# MSP430FR2355 register map
Vendor: msp430gen; File version: v0.4.0-28-gb0087ce-dirty
Registers are 16-bit, read-write, reset 0x0 unless marked. A register's access mark holds for its fields unless they carry their own. Offsets are from the block's base; [hi:lo] are bit positions; {n}, {i} and the like mark numbered series; 'fields as' and 'values as' point back to an identical list.

## SYS
Base 0x00000140
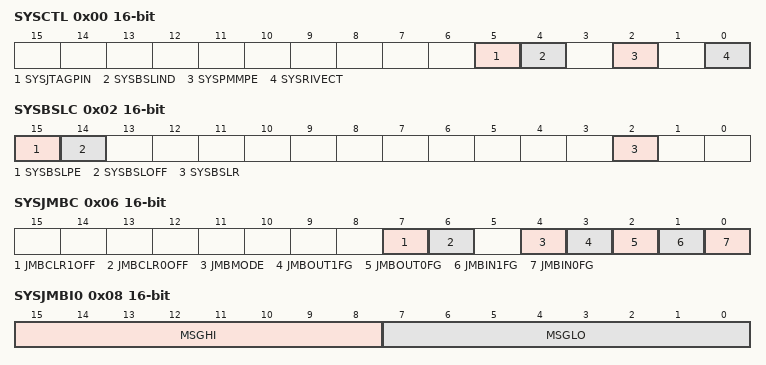
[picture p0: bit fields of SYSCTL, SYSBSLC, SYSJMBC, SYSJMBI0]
0x00 SYSCTL — System Control
  [5] SYSJTAGPIN — Dedicated JTAG pins enable
    0=SHARED (Shared JTAG pins (JTAG mode selectable by JTAG/SBW sequence)); 1=DEDICATED (Dedicated JTAG pins (explicit 4-wire JTAG mode selection))
  [4] SYSBSLIND — BSL entry indication
    0=CLR (No BSL entry sequence detected); 1=SET (BSL entry sequence detected)
  [2] SYSPMMPE — PMM access protect
    0=DIS (Access from anywhere in memory); 1=EN (Access only from the protected BSL segments)
  [0] SYSRIVECT — RAM-based interrupt vectors
    0=FRAM (Interrupt vectors generated with end address TOP of lower 64KB of FRAM FFFFh); 1=RAM (Interrupt vectors generated with end address TOP of RAM)
0x02 SYSBSLC — Bootstrap Loader Configuration Register
  [15] SYSBSLPE — Bootstrap loader memory protection enable for the size covered in SYSBSLSIZE. By default, this bit is cleared by hardware with a BOR event (as indicated above); however, the boot code that checks for an available BSL may set this bit in software to protect the BSL. Because devices normally come with a TI BSL preprogrammed and protected, the boot code sets this bit.
    0=NOTPROT (Area not protected. Read, program, and erase of BSL memory is possible.); 1=PROT (Area protected)
  [14] SYSBSLOFF — Bootstrap loader memory disable for the size covered in SYSBSLSIZE
    0=ON (BSL memory is addressed when this area is read.); 1=OFF (BSL memory behaves like vacant memory. Reads cause 3FFFh to be read. Fetches cause JMP $ to be executed.)
  [2] SYSBSLR — RAM assigned to BSL
    0=NORAM (No RAM assigned to BSL area); 1=RAM (Lowest 16 bytes of RAM assigned to BSL)
0x06 SYSJMBC — JTAG Mailbox Control
  [7] JMBCLR1OFF — Incoming JTAG Mailbox 1 flag auto-clear disable
    0=JMBIN1FG cleared on read of JMB1IN register; 1=JMBIN1FG cleared by software
  [6] JMBCLR0OFF — Incoming JTAG Mailbox 0 flag auto-clear disable
    0=JMBIN0FG cleared on read of JMB0IN register; 1=JMBIN0FG cleared by software
  [4] JMBMODE — Operation mode of JMB
    0=16BIT (16-bit transfers using JMBO0 and JMBI0 only); 1=32BIT (32-bit transfers using JMBO0 with JMBO1 and JMBI0 with JMBI1)
  [3] JMBOUT1FG ro — Outgoing JTAG Mailbox 1 flag
    0=JMBO1 is not ready to receive new data; 1=JMBO1 is ready to receive new data
  [2] JMBOUT0FG ro — Outgoing JTAG Mailbox 0 flag
    0=JMBO0 is not ready to receive new data; 1=JMBO0 is ready to receive new data
  [1] JMBIN1FG — Incoming JTAG Mailbox 1 flag
    0=JMBI1 has no new data; 1=JMBI1 has new data available
  [0] JMBIN0FG — Incoming JTAG Mailbox 0 flag
    0=JMBI0 has no new data; 1=JMBI0 has new data available
0x08 SYSJMBI0 — JTAG Mailbox Input
  [15:8] MSGHI — JTAG mailbox incoming message high byte
  [7:0] MSGLO — JTAG mailbox incoming message low byte
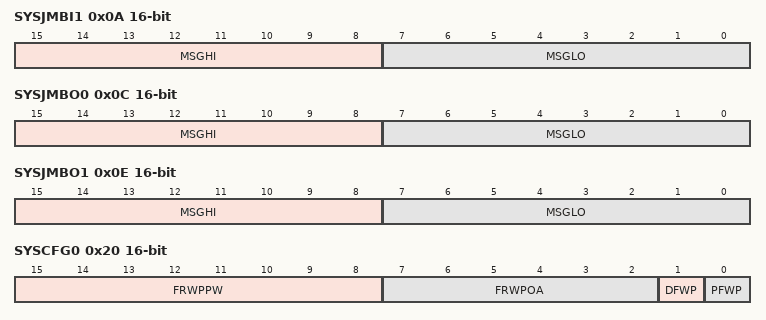
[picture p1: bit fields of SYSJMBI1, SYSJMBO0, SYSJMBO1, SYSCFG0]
0x0A SYSJMBI1 — JTAG Mailbox Input 1 Register
  fields as SYSJMBI0
0x0C SYSJMBO0 — JTAG Mailbox Output
  [15:8] MSGHI — JTAG mailbox outgoing message high byte
  [7:0] MSGLO — JTAG mailbox outgoing message low byte
0x0E SYSJMBO1 — JTAG Mailbox Output 1 Register
  fields as SYSJMBO0
0x1A SYSUNIV — User NMI Vector Generator
  [15:0] SYSUNIV ro — User NMI vector
    2=NMI_PIN (NMIIFG NMI pin or SVSH event); 4=OSCILLATOR_FAULT (OFIFG oscillator fault)
0x1C SYSSNIV — System NMI Vector Generator
  [15:0] SYSSNIV ro — System NMI vector
    2=SVS_LOW_POWER_RESET_ENTRY; 4=FRAM_UNCORRECTABLE_BIT_ERROR (Uncorrectable FRAM bit error detection); 18=VACANT_MEMORY_ACCESS (VMAIFG vacant memory access); 20=JTAG_MAILBOX_IN (JMBINIFG JTAG mailbox input); 22=JTAG_MAILBOX_OUT (JMBOUTIFG JTAG mailbox output); 24=FRAM_CORRECTABLE_BIT_ERROR (Correctable FRAM bit error detection)
0x1E SYSRSTIV — Reset Vector Generator
  [15:0] SYSRSTIV ro — Reset interrupt vector
    2=BROWNOUT (Brownout (BOR)); 4=RESET_PIN (RSTIFG RST/NMI (BOR)); 6=SOFTWARE_BOR (PMMSWBOR software BOR (BOR)); 8=LPMX5_WAKE_UP (LPMx.5 wakeup (BOR)); 10=SECURITY_VIOLATION (Security violation (BOR)); 14=SVSH (SVSHIFG SVSH event (BOR)); 20=SOFTWARE_POR (PMMSWPOR software POR (POR)); 22=WATCHDOG_TIMEOUT (WDTIFG watchdog time-out (PUC)); 24=WATCHDOG_PASSWORD (WDTPW password violation (PUC)); 26=FRAM_PASSWORD (FRCTLPW password violation (PUC)); 28=FRAM_BIT_ERROR (Uncorrectable FRAM bit error detection); 30=PERIPHERAL_AREA_FETCH (Peripheral area fetch (PUC)); 32=PMM_PASSWORD (PMMPW PMM password violation (PUC)); 36=FLL_UNLOCK (FLL unlock (PUC))
0x20 SYSCFG0 — System Configuration Register 0
  [15:8] FRWPPW — FRAM protection password, FRAM protection password. Write with 0A5h to unlock the FRAM protection registers. Always reads as 096h
    on read: 150=PASSWORD (Value always read from the SYSCFG0 password field) | on write: 165=PASSWORD (Value which must be written to the SYSCFG0 password field)
  [7:2] FRWPOA — Program FRAM write protection offset address from the beginning of Program FRAM. The offset increases by 1KB resolution
  [1] DFWP — Data FRAM write protection
    0=Data FRAM write enable; 1=Data FRAM write protected (not writable)
  [0] PFWP — Program FRAM write protection
    0=Program FRAM write enable; 1=Program FRAM write protected (not writable)
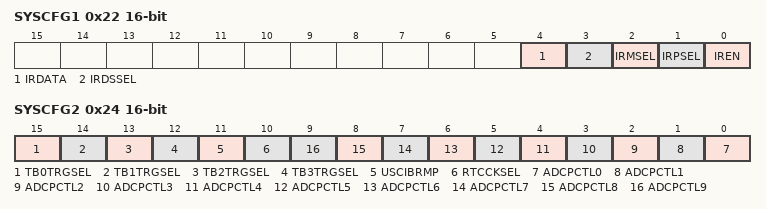
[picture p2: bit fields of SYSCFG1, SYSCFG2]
0x22 SYSCFG1 — System Configuration Register 1
  [4] IRDATA — Infrared data
    0=Infrared data logic 0; 1=Infrared data logic 1
  [3] IRDSSEL — Infrared data source select
    0=From hardware peripherals upon device configuration; 1=From IRDATA bit
  [2] IRMSEL — Infrared mode select
    0=ASK (ASK mode); 1=FSK (FSK mode)
  [1] IRPSEL — Infrared polarity select
    0=Normal polarity; 1=Inverted polarity
  [0] IREN — Infrared enable
    0=Infrared function disabled; 1=Infrared function enabled
0x24 SYSCFG2 — System Configuration Register 2
  [15] TB0TRGSEL — TB0OUTH trigger select
    0=Internal source selected (eCOMP0); 1=External source selected (TB0TRG pin)
  [14] TB1TRGSEL — TB1OUTH trigger select
    0=Internal source selected (eCOMP0); 1=External source selected (TB1TRG pin)
  [13] TB2TRGSEL — TB2OUTH trigger select
    0=Internal source selected (eCOMP1); 1=External source selected (TB2TRG pin)
  [12] TB3TRGSEL — TB3OUTH trigger select
    0=Internal source selected (eCOMP1); 1=External source selected (not available)
  [11] USCIBRMP — eUSCIB Remapping source selection , please refer to device specific for details
    0=P1.x is selected, please refer to device specific for details; 1=other port is selected, please refer to device specific for details
  [10] RTCCKSEL — RTC clock selection
    0=RTC_SMCLK (SMCLK is selected); 1=RTC_ACLK (ACLK is selected)
  [n] ADCPCTL{n} (n=0..9) — ADC input A{n} pin select
    0=ADC input A{n} disabled; 1=ADC input A{n} enabled
0x26 SYSCFG3 — System Configuration Register 3
  [0] USCIARMP — eUSCIA remapping source selection, please refer to device specific for details
    values as SYSCFG2.USCIBRMP
